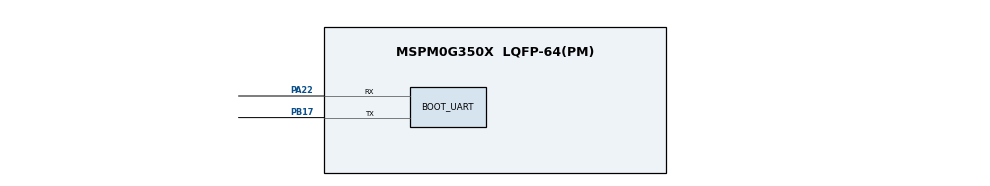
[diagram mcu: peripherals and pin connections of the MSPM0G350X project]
/**
 * @cliArgs --device "MSPM0G350X" --part "Default" --package "LQFP-64(PM)" --product "mspm0_sdk@2.10.00.04"
 */

const UART          = scripting.addModule("/ti/driverlib/UART", {}, false);
const BOOT_UART     = UART.addInstance();
const SYSCTL        = scripting.addModule("/ti/driverlib/SYSCTL");
const ProjectConfig = scripting.addModule("/ti/project_config/ProjectConfig");

const divider9       = system.clockTree["UDIV"];
divider9.divideValue = 2;
const mux4       = system.clockTree["EXHFMUX"];
mux4.inputSelect = "EXHFMUX_XTAL";
const mux8       = system.clockTree["HSCLKMUX"];
mux8.inputSelect = "HSCLKMUX_SYSPLL2X";
const mux12       = system.clockTree["SYSPLLMUX"];
mux12.inputSelect = "zSYSPLLMUX_HFCLK";
const hfxIn       = system.clockTree["HFXT"];
hfxIn.inputFreq   = 40;
hfxIn.HFXTStartup = 10;
hfxIn.enable      = true;

BOOT_UART.$name                            = "BOOT_UART";
BOOT_UART.targetBaudRate                   = 115200;
BOOT_UART.enableFIFO                       = true;
BOOT_UART.rxFifoThreshold                  = "DL_UART_RX_FIFO_LEVEL_ONE_ENTRY";
BOOT_UART.peripheral.$assign               = "UART2";
BOOT_UART.peripheral.rxPin.$assign         = "PA22";
BOOT_UART.peripheral.txPin.$assign         = "PB17";
BOOT_UART.txPinConfig.direction            = scripting.forceWrite("OUTPUT");
BOOT_UART.txPinConfig.hideOutputInversion  = scripting.forceWrite(false);
BOOT_UART.txPinConfig.onlyInternalResistor = scripting.forceWrite(false);
BOOT_UART.txPinConfig.passedPeripheralType = scripting.forceWrite("Digital");
BOOT_UART.rxPinConfig.hideOutputInversion  = scripting.forceWrite(false);
BOOT_UART.rxPinConfig.onlyInternalResistor = scripting.forceWrite(false);
BOOT_UART.rxPinConfig.passedPeripheralType = scripting.forceWrite("Digital");

SYSCTL.clockTreeEn = true;
ProjectConfig.genLibCMSIS = false;
hfxIn.peripheral.$suggestSolution          = "SYSCTL";
hfxIn.peripheral.hfxInPin.$suggestSolution = "PA5";
hfxIn.peripheral.hfxOutPin.$suggestSolution = "PA6";
